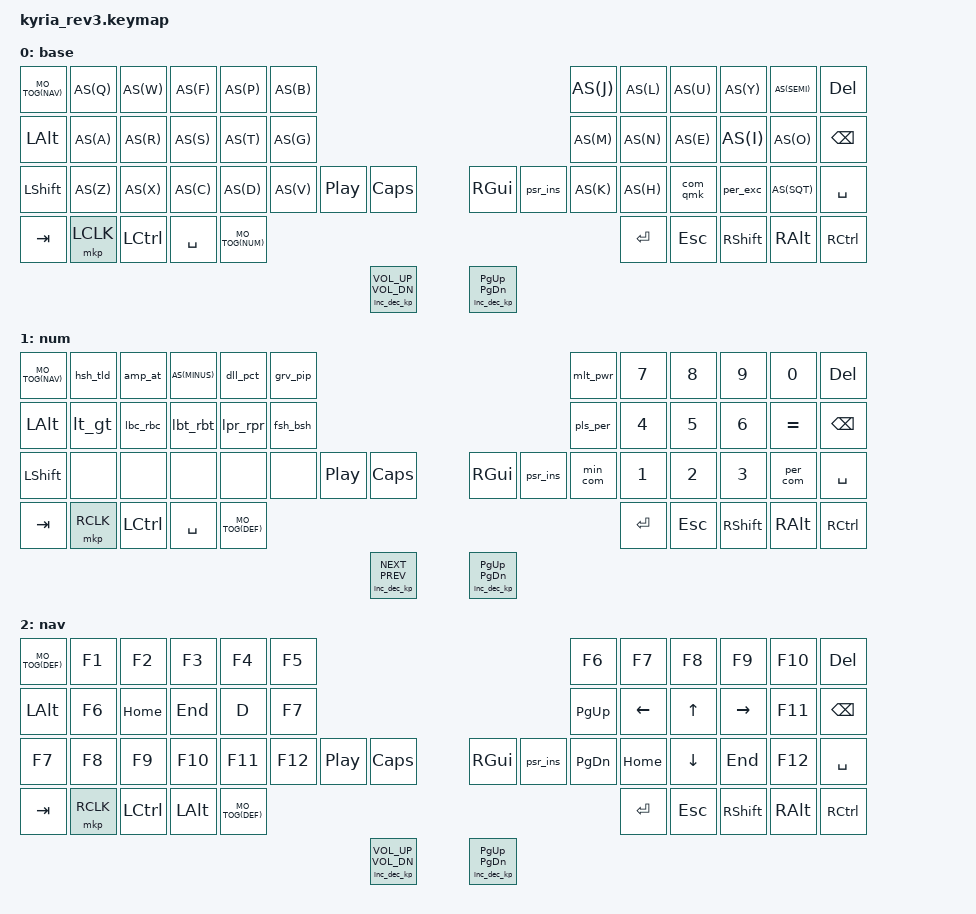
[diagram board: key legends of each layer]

#include <dt-bindings/zmk/bt.h>
#include <dt-bindings/zmk/keys.h>
#include <dt-bindings/zmk/mouse.h>
#include <dt-bindings/zmk/ext_power.h>
#include <dt-bindings/zmk/backlight.h>
#include <dt-bindings/zmk/outputs.h>
#include <dt-bindings/zmk/rgb.h>
#include <dt-bindings/zmk/ext_power.h>
// #include <drivers/zmk/ext_power.h>
#include <behaviors.dtsi>

/* Uncomment this block if using RGB
&led_strip {
    chain-length = <6>;
    // chain-length = <31>; // Uncomment if using both per-key and underglow LEDs
    // chain-length = <25>; // Uncomment if using only per-key LEDs.
};
*/

//jbsoum add - macros from here: https://zmk.dev/docs/behaviors/hold-tap
#define AS(keycode) &as LS(keycode) keycode     // Autoshift Macro
#define MO_TOG(layer) &mo_tog layer layer   // Macro to apply momentary-layer-on-hold/toggle-layer-on-tap to a specific layer

// #include "../zmk-nodefree-config/helper.h"
// #include "../config/keypos_kyria_rev3.h"

#include "zmk-helpers/helper.h"

// Source desired key-position labels
#include "zmk-helpers/key-labels/kyria.h"

// Source unicode-chars for desired languages
// #include "zmk-helpers/unicode-chars/german.dtsi"

/* layer and key shortcuts */

#define ___ &trans

#define DEF 0  // layer shortcuts, must match order in which they are defined below
#define NUM 1
#define NAV 2

/* custom behaviors */

//jbsoum add - autoshift macro from here: https://zmk.dev/docs/behaviors/hold-tap
ZMK_BEHAVIOR(as, hold_tap,
     tapping_term_ms = <200>;
     quick_tap_ms = <0>;
     flavor = "tap-preferred";
     bindings = <&kp>, <&kp>;
)
//jbsoum add - momentary layer when held, to layer when tapped, from here: https://zmk.dev/docs/behaviors/hold-tap
ZMK_BEHAVIOR(mo_tog, hold_tap,
     flavor = "hold-preferred";
     tapping-term-ms = <200>;
     bindings = <&mo>, <&to>;
)
//jbsoum add - crosshand only modifiers, from here: https://zmk.dev/docs/behaviors/hold-tap
// ZMK_BEHAVIOR(lh_pht, hold_tap,
//      flavor = "tap-unless-interrupted";
//      tapping-term-ms = <100>;                        // <---[[produces tap if held longer than tapping-term-ms]]
//      quick-tap-ms = <200>;
//      bindings = <&kp>, <&kp>;
//      hold-trigger-key-positions = <RM0 RM1 RM2 RM3 RM4 RM5>;    // <---[[right-hand keys]]
// )
// ZMK_BEHAVIOR(rh_pht, hold_tap,
//      flavor = "tap-unless-interrupted";
//      tapping-term-ms = <100>;                        // <---[[produces tap if held longer than tapping-term-ms]]
//      quick-tap-ms = <200>;
//      bindings = <&kp>, <&kp>;
//      hold-trigger-key-positions = <LM5 LM4 LM3 LM2 LM1 LM0>;    // <---[[left-hand keys]]
// )
// undo fix for VBA (use Alt, E, R, Enter instead, works for most office products) (jbsoum add)
// ZMK_BEHAVIOR(alt_redo, macro,
//      bindings
//           = <&macro_tap &kp LALT>
//           , <&macro_tap &kp E>
//           , <&macro_tap &kp R>
//           , <&macro_tap &kp ENTER> 
//           ;
// )

/* jbsoum add - power key */ 

ZMK_BEHAVIOR(mc_hold_pow, macro, 
     bindings 
          = <&ext_power EP_TOG>
          ;
)
ZMK_BEHAVIOR(mc_tap_pow, macro, 
     bindings 
          = <&rgb_ug RGB_TOG &out OUT_TOG>
          ;
)
ZMK_BEHAVIOR(ht_pow, hold_tap,
     tapping_term_ms = <200>;
     quick_tap_ms = <0>;
     flavor = "tap-preferred";
     bindings = <&mc_hold_pow>, <&mc_tap_pow>;
)
ZMK_BEHAVIOR(pow, mod_morph,
     bindings = <&ht_pow 0 0>, <&mc_hold_pow 0>;
     mods = <(MOD_LSFT|MOD_RSFT)>;
)


#define OPTS_HT(name)    tapping_term_ms = <200>; quick_tap_ms = <0>; flavor = "tap-preferred"; bindings = <&mc_hold_ ## name>, <&mc_tap_ ## name>;
#define OPTS_MM(name)    bindings = <&ht_ ## name 0 0>, <&mc_hold_ ## name 0>; mods = <(MOD_LSFT|MOD_RSFT)>;

#define J_BEHAVIOR_CUSTOM_ht(name, tap_kp, hold_kp) \
     ZMK_BEHAVIOR(mc_hold_ ## name, macro, bindings = <&macro_press &kp hold_kp>, <&macro_release &kp hold_kp>;) \
     ZMK_BEHAVIOR(mc_tap_ ## name, macro, bindings = <&macro_tap &kp tap_kp>;) \
     ZMK_BEHAVIOR(ht_ ## name, hold_tap, OPTS_HT(name))

#define J_BEHAVIOR_CUSTOM_mht(name, tap_kp, hold_kp) \
     ZMK_BEHAVIOR(mc_hold_ ## name, macro, bindings = <&macro_press &mkp hold_kp>, <&macro_release &mkp hold_kp>;) \
     ZMK_BEHAVIOR(mc_tap_ ## name, macro, bindings = <&macro_tap &mkp tap_kp>;) \
     ZMK_BEHAVIOR(ht_ ## name, hold_tap, OPTS_HT(name))

#define J_BEHAVIOR_CUSTOM_mm(name) ZMK_BEHAVIOR(name, mod_morph, OPTS_MM(name))

#define HT(name) &ht_ ## name 0 0


// custom shift keys - typing layer (jbsoum add)
J_BEHAVIOR_CUSTOM_mht(mbl_mbr, LCLK, RCLK)
J_BEHAVIOR_CUSTOM_mm(mbl_mbr)
J_BEHAVIOR_CUSTOM_mm(com_qmk)
J_BEHAVIOR_CUSTOM_ht(com_qmk, COMMA, QMARK)
J_BEHAVIOR_CUSTOM_mm(com_qmk)
J_BEHAVIOR_CUSTOM_ht(per_exc, PERIOD, EXCL)
J_BEHAVIOR_CUSTOM_mm(per_exc)
J_BEHAVIOR_CUSTOM_ht(amp_at, AMPS, AT)
J_BEHAVIOR_CUSTOM_mm(amp_at)
J_BEHAVIOR_CUSTOM_ht(fsh_min, FSLH, MINUS)
J_BEHAVIOR_CUSTOM_mm(fsh_min)
J_BEHAVIOR_CUSTOM_ht(bsh_und, BSLH, UNDER)
J_BEHAVIOR_CUSTOM_mm(bsh_und)
J_BEHAVIOR_CUSTOM_ht(hsh_tld, HASH, TILDE)
J_BEHAVIOR_CUSTOM_mm(hsh_tld)
J_BEHAVIOR_CUSTOM_ht(dll_pct, DOLLAR, PERCENT)
J_BEHAVIOR_CUSTOM_mm(dll_pct)

// custom shift keys - number layer (jbsoum add)
J_BEHAVIOR_CUSTOM_ht(pls_per, PLUS, PERIOD)
J_BEHAVIOR_CUSTOM_mm(pls_per)
J_BEHAVIOR_CUSTOM_ht(min_com, MINUS, COMMA)
J_BEHAVIOR_CUSTOM_mm(min_com)
J_BEHAVIOR_CUSTOM_ht(mlt_pwr, STAR, CARET)
J_BEHAVIOR_CUSTOM_mm(mlt_pwr)
J_BEHAVIOR_CUSTOM_ht(div_dll, FSLH, DOLLAR)
J_BEHAVIOR_CUSTOM_mm(div_dll)
J_BEHAVIOR_CUSTOM_ht(eql_pct, EQUAL, PERCENT)
J_BEHAVIOR_CUSTOM_mm(eql_pct)
J_BEHAVIOR_CUSTOM_ht(fsh_dll, FSLH, DOLLAR)
J_BEHAVIOR_CUSTOM_mm(fsh_dll)
J_BEHAVIOR_CUSTOM_ht(grv_pip, GRAVE, PIPE)
J_BEHAVIOR_CUSTOM_mm(grv_pip)
J_BEHAVIOR_CUSTOM_ht(per_com, PERIOD, COMMA)
J_BEHAVIOR_CUSTOM_mm(per_com)

// custom shift keys - brackets (jbsoum add)
J_BEHAVIOR_CUSTOM_ht(fsh_bsh, FSLH, BSLH)
J_BEHAVIOR_CUSTOM_mm(fsh_bsh)
J_BEHAVIOR_CUSTOM_ht(lpr_rpr, LPAR, RPAR)
J_BEHAVIOR_CUSTOM_mm(lpr_rpr)
J_BEHAVIOR_CUSTOM_ht(lbt_rbt, LBKT, RBKT)
J_BEHAVIOR_CUSTOM_mm(lbt_rbt)
J_BEHAVIOR_CUSTOM_ht(lbc_rbc, LBRC, RBRC)
J_BEHAVIOR_CUSTOM_mm(lbc_rbc)
J_BEHAVIOR_CUSTOM_ht(lt_gt, LT, GT)
J_BEHAVIOR_CUSTOM_mm(lt_gt)

// custom shift keys - actions (jbsoum add)
J_BEHAVIOR_CUSTOM_ht(hme_end, HOME, END)
J_BEHAVIOR_CUSTOM_ht(bsp_del, BACKSPACE, DELETE)
J_BEHAVIOR_CUSTOM_ht(psr_ins, PRINTSCREEN, INSERT)
J_BEHAVIOR_CUSTOM_mm(psr_ins)
J_BEHAVIOR_CUSTOM_ht(tab_cap, TAB, CAPSLOCK)
J_BEHAVIOR_CUSTOM_mm(tab_cap)
J_BEHAVIOR_CUSTOM_ht(ent_esc, ENTER, ESC)

// layer buttons (jbsoum add)
// ZMK_BEHAVIOR(ly_def, macro,
//      bindings 
//           = <&macro_tap &to DEF>
//           , <&rgb_ug RGB_COLOR_HSB(45,20,100)>
//           ;
//  )
// ZMK_BEHAVIOR(ly_numhld, macro,
//      bindings 
//           // = <&macro_tap &rgb_ug RGB_COLOR_HSB(110,25,100)>
//           = <&macro_tap>
//           , <&macro_press &mo NUM>
//           , <&macro_pause_for_release>
//           , <&macro_release &mo NUM>
//           , <&macro_tap>
//           // , <&macro_tap &rgb_ug RGB_COLOR_HSB(45,20,100)>
//           ;
//  )
// ZMK_BEHAVIOR(ly_numtap, macro,
//      bindings 
//           = <&macro_tap &to NUM>
//           // , <&macro_tap &rgb_ug RGB_COLOR_HSB(110,25,100)>
//           ;
//  )
// ZMK_BEHAVIOR(ly_navhld, macro,
//      bindings 
//           // = <&rgb_ug RGB_COLOR_HSB(170,25,100)>
//           = <&macro_tap>          
//           , <&macro_press &mo NAV>
//           , <&macro_pause_for_release>
//           , <&macro_release &mo NAV>
//                     = <&macro_tap>
//           // , <&macro_tap &rgb_ug RGB_COLOR_HSB(45,20,100)>
//           ;
// )
// ZMK_BEHAVIOR(ly_navtap, macro,
//      bindings 
//           = <&macro_tap &to NAV>   
//           // , <&macro_tap &rgb_ug RGB_COLOR_HSB(170,25,100)>
//           ;
// )

// ZMK_BEHAVIOR(ly_num, hold_tap,
//      flavor = "hold-preferred";
//      tapping_term_ms = <150>;
//      quick_tap_ms = <-1>;
//      bindings = <&ly_numhld>, <&ly_numtap>;
// )

// ZMK_BEHAVIOR(ly_nav, hold_tap,
//      flavor = "hold-preferred";
//      tapping_term_ms = <150>;
//      quick_tap_ms = <-1>;
//      bindings = <&ly_navhld>, <&ly_navtap>;
// )

// ZMK_BEHAVIOR(ly, mod_morph,
//      bindings = <&ly_num 0 0>, <&ly_nav 0>;
//      mods = <(MOD_RCTL|MOD_LCTL)>;
// )


/* homerow mods */ // from nodefree config

// tap: sticky shift | double tap: capsword
//ZMK_BEHAVIOR(ss_cw, tap_dance,
//     tapping-term-ms = <200>;
//     bindings = <&sk LSHFT>, <&caps_word>;
// )

// tap: backspace | shift + tap: delete | hold: num layer
//ZMK_BEHAVIOR(bs_del_num, mod_morph,
//    bindings = <&lt NUM BSPC>, <&kp DEL>;
//    mods = <(MOD_LSFT|MOD_RSFT)>;
//)

// windows sleep macro
ZMK_BEHAVIOR(win_sleep, macro,
    wait-ms = <100>;
    tap-ms = <5>;
    bindings = <&kp LG(X) &kp U &kp S>;
)

// euro sign
//ZMK_UNICODE_SINGLE(euro_sign, N2, N0, A, C)  // €

// replace a/o/u/s with German umlauts when NAV and NUM are held jointly
//ZMK_CONDITIONAL_LAYER(NAV NUM, GER)

// combos
#undef COMBO_TERM
#define COMBO_TERM 40  // timeout of 40ms (default is 30ms if omitted)
ZMK_COMBO(combo_sleep,  &win_sleep, LB5 LM2, ALL)  // custom sleep macro, active on all layers
ZMK_COMBO(combo_copy,   &kp LC(C),  LB2 LH4, ALL)  // Ctrl + C, active on all layers
ZMK_COMBO(combo_paste,  &kp LC(V),  LB0 LH4, ALL)  // Ctrl + V, active on all layers

// #define MS &mo_tog LCLK RCLK
/* keymap */

ZMK_LAYER(base,
     // ╭─────────────┬─────────────┬─────────────┬─────────────┬─────────────┬─────────────╮                                                           ╭─────────────┬─────────────┬─────────────┬─────────────┬─────────────┬─────────────╮
         MO_TOG(NAV)   AS(Q)         AS(W)         AS(F)         AS(P)         AS(B)                                                                     AS(J)         AS(L)         AS(U)         AS(Y)         AS(SEMI)      &kp DEL
     // ├─────────────┼─────────────┼─────────────┼─────────────┼─────────────┼─────────────┤                                                           ├─────────────┼─────────────┼─────────────┼─────────────┼─────────────┼─────────────┤
         &kp LALT      AS(A)         AS(R)         AS(S)         AS(T)         AS(G)                                                                     AS(M)         AS(N)         AS(E)         AS(I)         AS(O)         &kp BSPC 
     // ├─────────────┼─────────────┼─────────────┼─────────────┼─────────────┼─────────────┬─────────────┬─────────────╮   ╭─────────────┬─────────────┬─────────────┼─────────────┼─────────────┼─────────────┼─────────────┼─────────────┤
         &kp LSHFT     AS(Z)         AS(X)         AS(C)         AS(D)         AS(V)         &kp C_PP      &kp CAPSLOCK      &kp RGUI      &psr_ins      AS(K)         AS(H)         &com_qmk      &per_exc      AS(SQT)       &kp SPACE
     // ╰─────────────┴─────────────┴─────────────┼─────────────┼─────────────┼─────────────┼─────────────┼─────────────┤   ├─────────────┼─────────────┼─────────────┼─────────────┼─────────────┼─────────────┴─────────────┴─────────────╯
                                                   &kp TAB       &mkp LCLK     &kp LCTRL     &kp SPACE     MO_TOG(NUM)       &kp ENTER     &kp ESC       &kp RSHFT     &kp RALT      &kp RCTRL
     //                                           ╰─────────────┴─────────────┴─────────────┴─────────────┴─────────────╯   ╰─────────────┴─────────────┴─────────────┴─────────────┴─────────────╯
     , &inc_dec_kp C_VOL_UP C_VOL_DN &inc_dec_kp PG_UP PG_DN
)

ZMK_LAYER(num,
     // ╭─────────────┬─────────────┬─────────────┬─────────────┬─────────────┬─────────────╮                                                           ╭─────────────┬─────────────┬─────────────┬─────────────┬─────────────┬─────────────╮
         MO_TOG(NAV)   &hsh_tld      &amp_at       AS(MINUS)     &dll_pct      &grv_pip                                                                  &mlt_pwr      &kp N7        &kp N8        &kp N9        &kp N0        &kp DEL
     // ├─────────────┼─────────────┼─────────────┼─────────────┼─────────────┼─────────────┤                                                           ├─────────────┼─────────────┼─────────────┼─────────────┼─────────────┼─────────────┤
         &kp LALT      &lt_gt        &lbc_rbc      &lbt_rbt      &lpr_rpr      &fsh_bsh                                                                  &pls_per      &kp N4        &kp N5        &kp N6        &kp EQUAL     &kp BSPC 
     // ├─────────────┼─────────────┼─────────────┼─────────────┼─────────────┼─────────────┬─────────────┬─────────────╮   ╭─────────────┬─────────────┬─────────────┼─────────────┼─────────────┼─────────────┼─────────────┼─────────────┤
         &kp LSHFT     &none         &none         &none         &none         &none         &kp C_PP      &kp CAPSLOCK      &kp RGUI      &psr_ins      &min_com      &kp N1        &kp N2        &kp N3        &per_com      &kp SPACE
     // ╰─────────────┴─────────────┴─────────────┼─────────────┼─────────────┼─────────────┼─────────────┼─────────────┤   ├─────────────┼─────────────┼─────────────┼─────────────┼─────────────┼─────────────┴─────────────┴─────────────╯
                                                   &kp TAB       &mkp RCLK     &kp LCTRL     &kp SPACE     MO_TOG(DEF)       &kp ENTER     &kp ESC       &kp RSHFT     &kp RALT      &kp RCTRL
     //                                           ╰─────────────┴─────────────┴─────────────┴─────────────┴─────────────╯   ╰─────────────┴─────────────┴─────────────┴─────────────┴─────────────╯
     , &inc_dec_kp C_NEXT C_PREV &inc_dec_kp PG_UP PG_DN
)

ZMK_LAYER(nav,
     // ╭─────────────┬─────────────┬─────────────┬─────────────┬─────────────┬─────────────╮                                                           ╭─────────────┬─────────────┬─────────────┬─────────────┬─────────────┬─────────────╮
         MO_TOG(DEF)   &kp F1        &kp F2        &kp F3        &kp F4        &kp F5                                                                    &kp F6        &kp F7        &kp F8        &kp F9        &kp F10       &kp DEL
     // ├─────────────┼─────────────┼─────────────┼─────────────┼─────────────┼─────────────┤                                                           ├─────────────┼─────────────┼─────────────┼─────────────┼─────────────┼─────────────┤ 
         &kp LALT      &kp F6        &kp HOME      &kp END       &kp D         &kp F7                                                                    &kp PG_UP     &kp LEFT      &kp UP        &kp RIGHT     &kp F11       &kp BSPC 
     // ├─────────────┼─────────────┼─────────────┼─────────────┼─────────────┼─────────────┬─────────────┬─────────────╮   ╭─────────────┬─────────────┬─────────────┼─────────────┼─────────────┼─────────────┼─────────────┼─────────────┤
         &kp F7        &kp F8        &kp F9        &kp F10       &kp F11       &kp F12       &kp C_PP      &kp CAPSLOCK      &kp RGUI      &psr_ins      &kp PG_DN     &kp HOME      &kp DOWN      &kp END       &kp F12       &kp SPACE
     // ╰─────────────┴─────────────┴─────────────┼─────────────┼─────────────┼─────────────┼─────────────┼─────────────┤   ├─────────────┼─────────────┼─────────────┼─────────────┼─────────────┼─────────────┴─────────────┴─────────────╯
                                                   &kp TAB       &mkp RCLK     &kp LCTRL     &kp LALT      MO_TOG(DEF)       &kp ENTER     &kp ESC       &kp RSHFT     &kp RALT      &kp RCTRL
     //                                           ╰─────────────┴─────────────┴─────────────┴─────────────┴─────────────╯   ╰─────────────┴─────────────┴─────────────┴─────────────┴─────────────╯
     , &inc_dec_kp C_VOL_UP C_VOL_DN &inc_dec_kp PG_UP PG_DN
)



/* default keymap for debugging */

// ZMK_LAYER(base,
//  	&dll_pct   HT(tab_cap) &kp E &kp R &kp T                                                &kp Y &kp U  &kp I     &kp O   &kp P    &kp BSLH
//  	&kp TAB   &kp A &kp S &kp D &kp F &kp G                                                &kp H &kp J  &kp K     &kp L   &kp SEMI &kp SQT
//  	&kp LSHFT &kp Z &kp X &kp C &kp V &kp B &kp LSHFT &kp LSHFT        &kp LSHFT &kp LSHFT &kp N &kp M  &kp COMMA &kp DOT &kp FSLH &kp RCTRL
//  	                 &kp LGUI &kp DEL &kp RET &kp SPACE &kp ESC        &kp RET  &kp SPACE  &kp TAB &kp BSPC &kp RALT
//      , &inc_dec_kp C_VOL_UP C_VOL_DN &inc_dec_kp PG_UP PG_DN
// )
